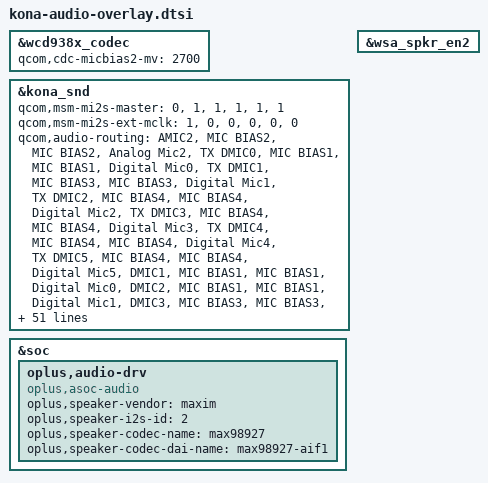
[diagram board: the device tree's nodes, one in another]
&wcd938x_codec {
	qcom,cdc-micbias2-mv = <2700>;
};

&kona_snd {
	qcom,msm-mi2s-master = <0>, <1>, <1>, <1>, <1>, <1>;
	qcom,msm-mi2s-ext-mclk = <1>, <0>, <0>, <0>, <0>, <0>;
	qcom,audio-routing =
		"AMIC2", "MIC BIAS2",
		"MIC BIAS2", "Analog Mic2",
		"TX DMIC0", "MIC BIAS1",
		"MIC BIAS1", "Digital Mic0",
		"TX DMIC1", "MIC BIAS3",
		"MIC BIAS3", "Digital Mic1",
		"TX DMIC2", "MIC BIAS4",
		"MIC BIAS4", "Digital Mic2",
		"TX DMIC3", "MIC BIAS4",
		"MIC BIAS4", "Digital Mic3",
		"TX DMIC4", "MIC BIAS4",
		"MIC BIAS4", "Digital Mic4",
		"TX DMIC5", "MIC BIAS4",
		"MIC BIAS4", "Digital Mic5",
		"DMIC1", "MIC BIAS1",
		"MIC BIAS1", "Digital Mic0",
		"DMIC2", "MIC BIAS1",
		"MIC BIAS1", "Digital Mic1",
		"DMIC3", "MIC BIAS3",
		"MIC BIAS3", "Digital Mic2",
		"DMIC4", "MIC BIAS3",
		"MIC BIAS3", "Digital Mic3",
		"DMIC5", "MIC BIAS4",
		"MIC BIAS4", "Digital Mic4",
		"DMIC6", "MIC BIAS4",
		"MIC BIAS4", "Digital Mic5",
		"IN1_HPHL", "HPHL_OUT",
		"IN2_HPHR", "HPHR_OUT",
		"IN3_AUX", "AUX_OUT",
		"TX SWR_ADC0", "ADC1_OUTPUT",
		"TX SWR_ADC1", "ADC2_OUTPUT",
		"TX SWR_ADC2", "ADC3_OUTPUT",
		"TX SWR_ADC3", "ADC4_OUTPUT",
		"TX SWR_DMIC0", "DMIC1_OUTPUT",
		"TX SWR_DMIC1", "DMIC2_OUTPUT",
		"TX SWR_DMIC2", "DMIC3_OUTPUT",
		"TX SWR_DMIC3", "DMIC4_OUTPUT",
		"TX SWR_DMIC4", "DMIC5_OUTPUT",
		"TX SWR_DMIC5", "DMIC6_OUTPUT",
		"TX SWR_DMIC6", "DMIC7_OUTPUT",
		"TX SWR_DMIC7", "DMIC8_OUTPUT",
		"WSA SRC0_INP", "SRC0",
		"WSA_TX DEC0_INP", "TX DEC0 MUX",
		"WSA_TX DEC1_INP", "TX DEC1 MUX",
		"RX_TX DEC0_INP", "TX DEC0 MUX",
		"RX_TX DEC1_INP", "TX DEC1 MUX",
		"RX_TX DEC2_INP", "TX DEC2 MUX",
		"RX_TX DEC3_INP", "TX DEC3 MUX",
		"SpkrLeft IN", "WSA_SPK1 OUT",
		"SpkrRight IN", "WSA_SPK2 OUT",
		"VA_AIF1 CAP", "VA_SWR_CLK",
		"VA_AIF2 CAP", "VA_SWR_CLK",
		"VA_AIF3 CAP", "VA_SWR_CLK",
		"VA MIC BIAS3", "Digital Mic0",
		"VA MIC BIAS3", "Digital Mic1",
		"VA MIC BIAS1", "Digital Mic2",
		"VA MIC BIAS1", "Digital Mic3",
		"VA MIC BIAS4", "Digital Mic4",
		"VA MIC BIAS4", "Digital Mic5",
		"VA DMIC0", "VA MIC BIAS3",
		"VA DMIC1", "VA MIC BIAS3",
		"VA DMIC2", "VA MIC BIAS1",
		"VA DMIC3", "VA MIC BIAS1",
		"VA DMIC4", "VA MIC BIAS4",
		"VA DMIC5", "VA MIC BIAS4",
		"VA SWR_ADC0", "VA_SWR_CLK",
		"VA SWR_ADC1", "VA_SWR_CLK",
		"VA SWR_ADC2", "VA_SWR_CLK",
		"VA SWR_ADC3", "VA_SWR_CLK",
		"VA SWR_MIC0", "VA_SWR_CLK",
		"VA SWR_MIC1", "VA_SWR_CLK",
		"VA SWR_MIC2", "VA_SWR_CLK",
		"VA SWR_MIC3", "VA_SWR_CLK",
		"VA SWR_MIC4", "VA_SWR_CLK",
		"VA SWR_MIC5", "VA_SWR_CLK",
		"VA SWR_MIC6", "VA_SWR_CLK",
		"VA SWR_MIC7", "VA_SWR_CLK",
		"VA SWR_ADC0", "ADC1_OUTPUT",
		"VA SWR_ADC1", "ADC2_OUTPUT",
		"VA SWR_ADC2", "ADC3_OUTPUT",
		"VA SWR_ADC3", "ADC4_OUTPUT",
		"VA SWR_MIC0", "DMIC1_OUTPUT",
		"VA SWR_MIC1", "DMIC2_OUTPUT",
		"VA SWR_MIC2", "DMIC3_OUTPUT",
		"VA SWR_MIC3", "DMIC4_OUTPUT",
		"VA SWR_MIC4", "DMIC5_OUTPUT",
		"VA SWR_MIC5", "DMIC6_OUTPUT",
		"VA SWR_MIC6", "DMIC7_OUTPUT",
		"VA SWR_MIC7", "DMIC8_OUTPUT";
	qcom,tert-mi2s-gpios = <&cdc_tert_mi2s_gpios>;
	qcom,msm-mbhc-hs-mic-max-threshold-mv = <2600>;
	qcom,msm-mbhc-hs-mic-min-threshold-mv = <75>;
	oppo,mbhc-check-cross-conn = <0>;
	qcom,msm-mbhc-usbc-audio-supported = <1>;
	qcom,wsa-max-devs = <0>;
};

&wsa_spkr_en2 {
	/delete-property/ pinctrl-names;
	/delete-property/ pinctrl-0;
	/delete-property/ pinctrl-1;
};

&soc {
	oplus,audio-drv {
		compatible = "oplus,asoc-audio";
		//for maxim speaker
		oplus,speaker-vendor = "maxim";
		oplus,speaker-i2s-id = <2>;
		oplus,speaker-codec-name = "max98927";
		oplus,speaker-codec-dai-name = "max98927-aif1";
	};
};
